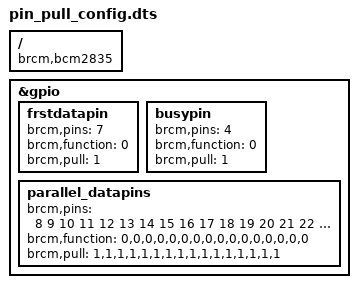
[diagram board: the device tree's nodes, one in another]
/dts-v1/;
/plugin/;

#include <dt-bindings/gpio/gpio.h>

/ {
    compatible = "brcm,bcm2835";
    fragment@0{
        target = <&gpio>;
        __overlay__{
                frstdatapin: frstdatapin {
                    brcm,pins = <7>;
                    brcm,function = <0>;
                    brcm,pull = <1>; 
            };
                busypin: busypin {
                    brcm,pins = <4>;
                    brcm,function = <0>;
                    brcm,pull = <1>; 
            };
                parallel_datapins: parallel_datapins {
                    brcm,pins = <8 9 10 11 12 13 14 15 16 17 18 19 20 21 22 23>;
                    brcm,function = <0,0,0,0,0,0,0,0,0,0,0,0,0,0,0,0>;
                    brcm,pull = <1,1,1,1,1,1,1,1,1,1,1,1,1,1,1,1>; 
            };
            
            

        };    
    };
};


